# NUC505_v1 register map
File version: 1.0
Registers are 32-bit, read-write, reset 0x0 unless marked. A register's access mark holds for its fields unless they carry their own. Offsets are from the block's base; [hi:lo] are bit positions; {n}, {i} and the like mark numbered series.

## I2S — I2S Register Map
Base 0x400E8000
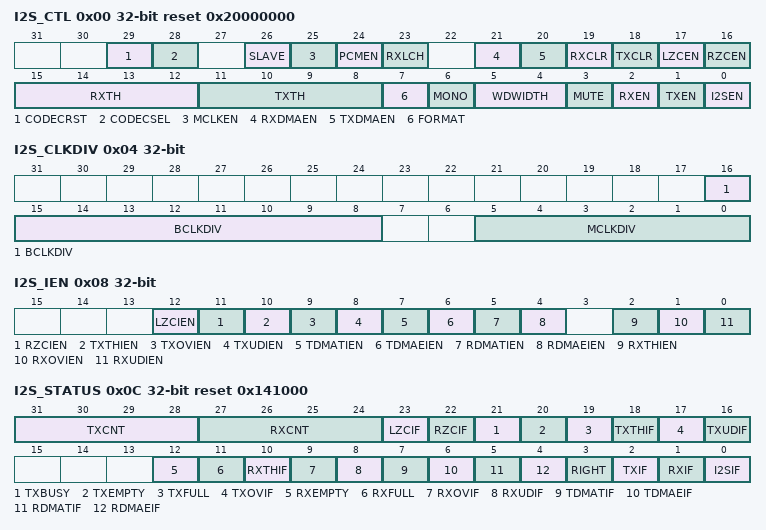
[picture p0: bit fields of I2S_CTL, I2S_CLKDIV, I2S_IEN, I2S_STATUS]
0x00 I2S_CTL reset 0x20000000 — I2S Control Register
  [29] CODECRST — Internal CODEC Hardware Reset Control
    0=Reset Operation; 1=Normal Operation
  [28] CODECSEL — Internal CODEC or External CODEC Selection
    0=I2S interface connected to internal CODEC; 1=I2S interface connected to external CODEC
  [26] SLAVE — Slave Mode. I2S can operate as master or slave. For Master mode, I2S_BCLK and I2S_LRCLK signals are output to CODEC. In Slave mode, I2S_BCLK and I2S_LRCLK pins are received from CODEC. Note: If using internal CODEC, the I2S must be master mode.
    0=Master mode; 1=Slave mode
  [25] MCLKEN — Master Clock Enable Control. Note1: I2S_MCLK is always output. Note2: I2S_MCLK frequency is controlled by MCLKDIV[5:0].
    0=I2S master clock output Disabled; 1=I2S master clock output Enabled
  [24] PCMEN — PCM Interface Enable Control
    0=I2S Interface; 1=PCM Interface
  [23] RXLCH — Receive Left Channel Enable Control
    0=Receives right channel data when monaural format is selected; 1=Receives left channel data when monaural format is selected
  [21] RXDMAEN — RX DMA Enable Control (Record Path). Note: The I2S_RXSTADDR will be updated to new setting only when RXDMAEN is from low to high. Therefore, if you want to change I2S_RXSTADDR, you should confirm RXDMAEN is disabled.
    0=RX DMA mode Disabled; 1=RX DMA mode Enabled
  [20] TXDMAEN — TX DMA Enable Control (Transmit Path). Note: The I2S_TXSTADDR will be updated to new setting only when TXDMAEN is from low to high. Therefore, if you want to change I2S_TXSTADDR, you should confirm TXDMAEN is disabled.
    0=TX DMA mode Disabled; 1=TX DMA mode Enabled
  [19] RXCLR — Clear Receive FIFO. Note: This bit will be cleared to 0 automatically. Note2: If clearing the receiver FIFO, RXCNT (I2S_STATUS[27:24]) returns to 0x0 and receiver FIFO becomes empty.
    0=No effect; 1=Receiver FIFO will be cleared
  [18] TXCLR — Clear Transmit FIFO. Note: This bit will be cleared to 0 automatically. Note2: If clearing the transmit FIFO, TXCNT (I2S_STATUS[31:28]) returns to 0x0 and transmit FIFO becomes empty.
    0=No effect; 1=Transmit FIFO will be cleared
  [17] LZCEN — Left Channel Zero-cross Detect Enable Control. If this bit is set to 1, when left channel data sign bit change or next shift data bits are all zero then LZCIF flag in I2S_STATUS register is set to 1.
    0=Left channel zero-cross detect Disabled; 1=Left channel zero-cross detect Enabled
  [16] RZCEN — Right Channel Zero-cross Detection Enable Control. If this bit is set to 1, when right channel data sign bit change or next shift data bits are all zero then RZCIF flag in I2S_STATUS register is set to 1.
    0=Right channel zero-cross detect Disabled; 1=Right channel zero-cross detect Enabled
  [15:12] RXTH — Receive FIFO Threshold Level. When received data word(s) in buffer is equal to or higher than threshold level then RXTHIF flag is set.
    {v}={v+1} word data in receive FIFO (v=0..15)
  [11:8] TXTH — Transmit FIFO Threshold Level. If remain data word (32 bits) in transmit FIFO is the same or less than threshold level then TXTHIF flag is set.
    0=0 word data in transmit FIFO; 1=1 word data in transmit FIFO; {v}={v} words data in transmit FIFO (v=2..7); 8=8 word data in transmit FIFO; 9=9 word data in transmit FIFO; {v}={v} words data in transmit FIFO (v=10..15)
  [7] FORMAT — Data Format Selection
    0=I2S data format. PCM mode A; 1=MSB justified data format. PCM mode B
  [6] MONO — Monaural Data
    0=Data is stereo format; 1=Data is monaural format
  [5:4] WDWIDTH — Word Width
    0=Data is 8-bit; 1=Data is 16-bit; 2=Data is 24-bit; 3=Data is 32-bit
  [3] MUTE — Transmit Mute Enable Control
    0=Transmit data is shifted from buffer; 1=Transmit data is fixed to zero
  [2] RXEN — Receive Enable Control
    0=Data receiving Disabled; 1=Data receiving Enabled
  [1] TXEN — Transmit Enable Control
    0=Data transmission Disabled; 1=Data transmission Enabled
  [0] I2SEN — I2S Controller Enable Control
    0=Disabled; 1=Enabled
0x04 I2S_CLKDIV — I2S Clock Divider Control Register
  [16:8] BCLKDIV — Bit Clock Divider. User can program these bits to generate the frequency of BCLK, when I2S operates in master mode. In Slave mode, the frequency of BCLK is controlled by master device.
  [5:0] MCLKDIV — Master Clock Divider. If F_I2SCLK is (2*MCLKDIV)*256*F_LRCLK then software can program these bits to generate 256*F_LRCLK clock frequency as master clock to audio CODEC. But if MCLKDIV is set to 0, MCLK is the same as I2SCLK input.
0x08 I2S_IEN — I2S Interrupt Enable Register
  [all] fields
    0=Interrupt Disabled; 1=Interrupt Enabled
  [12] LZCIEN — Left Channel Zero-cross Interrupt Enable Control. Interrupt occurs if this bit is set to 1 and left channel zero-cross is detected.
  [11] RZCIEN — Right Channel Zero-cross Interrupt Enable Control. Interrupt occurs if this bit is set to 1 and right channel zero-cross is detected.
  [10] TXTHIEN — Transmit FIFO Threshold Level Interrupt Enable Control. Interrupt occurs if this bit is set to 1 and data words in transmit FIFO is less than TXTH[3:0].
  [9] TXOVIEN — Transmit FIFO Overflow Interrupt Enable Control. Interrupt occurs if this bit is set to 1 and transmit FIFO overflow flag is set to 1.
  [8] TXUDIEN — Transmit FIFO Underflow Interrupt Enable Control. Interrupt occurs if this bit is set to 1 and transmit FIFO underflow flag is set to 1.
  [7] TDMATIEN — TX DMA Threshold Interrupt Enable Control. Interrupt occurs if this bit is set to 1 and DMA current address is equal to I2S_TXTHADDR register
  [6] TDMAEIEN — TX DMA End Interrupt Enable Control. Interrupt occurs if this bit is set to 1 and DMA current address is equal to I2S_TXEADDR register
  [5] RDMATIEN — RX DMA Threshold Interrupt Enable Control. Interrupt occurs if this bit is set to 1 and DMA current address is equal to I2S_RXTHADDR register
  [4] RDMAEIEN — RX DMA End Interrupt Enable Control. Interrupt occurs if this bit is set to 1 and DMA current address is equal to I2S_RXEADDR register
  [2] RXTHIEN — Receive FIFO Threshold Level Interrupt Enable Control. When data word in receive FIFO is equal to or higher then RXTH[3:0] and the RXTHIF bit is set to 1. If RXTHIEN bit is enabled, interrupt will occur.
  [1] RXOVIEN — Receive FIFO Overflow Interrupt Enable Control
  [0] RXUDIEN — Receive FIFO Underflow Interrupt Enable Control. If software reads receive FIFO when it is empty the RXUDIF flag in I2S_STATUS register is set to 1.
0x0C I2S_STATUS reset 0x141000
  [31:28] TXCNT — Transmit FIFO Level. These bits indicate word number in transmit FIFO
    0=No data or 16 words ( need to check the TX full flag); 1=1 word in transmit FIFO; 15=15 words in transmit FIFO
  [27:24] RXCNT — Receive FIFO Level. These bits indicate word number in receive FIFO
    0=No data or 16 words (need to check the RX full flag); 1=1 word in receive FIFO; 15=15 words in receive FIFO
  [23] LZCIF — Left Channel Zero-cross Flag. It indicates left channel next sample data sign bit is changed or all data bits are zero. Note: Write 1 to clear this bit to 0.
    0=No zero-cross; 1=Left channel zero-cross is detected
  [22] RZCIF — Right Channel Zero-cross Flag. It indicates right channel next sample data sign bit is changed or all data bits are zero. Note: Write 1 to clear this bit to 0.
    0=No zero-cross; 1=Right channel zero-cross is detected
  [21] TXBUSY — Transmit Busy. This bit is cleared to 0 when all data in transmit FIFO and shift buffer is shifted out. This bit is set to 1 when the first data is loaded to shift buffer. Note: This bit is read only.
    0=Transmit shift buffer is empty; 1=Transmit shift buffer is busy
  [20] TXEMPTY — Transmit FIFO Empty. This bit reflect data word number in transmit FIFO is zero. Note: This bit is read only.
    0=Not empty; 1=Empty
  [19] TXFULL — Transmit FIFO Full. This bit reflect data word number in transmit FIFO is 16. Note: This bit is read only.
    0=Not full; 1=Full
  [18] TXTHIF — Transmit FIFO Threshold Flag. When data word(s) in transmit FIFO is equal or lower than threshold value set in TXTH[3:0] the TXTHIF bit becomes to 1. It keeps at 1 till TXCNT[3:0] is higher than TXTH[3:0] after software write I2S_TX register. Note: This bit is read only.
    0=Data word(s) in FIFO is higher than threshold level; 1=Data word(s) in FIFO is equal or lower than threshold level
  [17] TXOVIF — Transmit FIFO Overflow Flag. Write data to transmit FIFO when it is full and this bit set to 1. Note: Write 1 to clear this bit to 0.
    0=No overflow; 1=Overflow
  [16] TXUDIF — Transmit FIFO Underflow Flag. When transmit FIFO is empty and shift logic hardware read data from data FIFO causes this set to 1. Note: Write 1 to clear this bit to 0.
    0=No underflow; 1=Underflow
  [12] RXEMPTY — Receive FIFO Empty. This bit reflects data words number in receive FIFO is zero. Note: This bit is read only.
    0=FIFO not empty; 1=FIFO empty
  [11] RXFULL — Receive FIFO Full. This bit reflect data words number in receive FIFO is 16. Note: This bit is read only.
    0=FIFO not full; 1=FIFO full
  [10] RXTHIF — Receive FIFO Threshold Flag. When data word(s) in receive FIFO is equal to or higher than the threshold value set in RXTH[3:0] the RXTHIF bit becomes to 1. It keeps at 1 till RXCNT[3:0] is less than RXTH[3:0] after software reads the I2S_RX register. Note: This bit is read only.
    0=Data word(s) in FIFO is lower than threshold level; 1=Data word(s) in FIFO is equal or higher than threshold level
  [9] RXOVIF — Receive FIFO Overflow Flag. When receive FIFO is full and receive hardware attempt write to data into receive FIFO this bit is set to 1, and data in 1st buffer is overwritten. Note: Write 1 to clear this bit to 0.
    0=No overflow occurred; 1=Overflow occurred
  [8] RXUDIF — Receive FIFO Underflow Flag. Read receive FIFO when it is empty. Setting this bit to 1 indicates underflow occurred. Note: Write 1 to clear this bit to zero
    0=No underflow occurred; 1=Underflow occurred
  [7] TDMATIF — TX DMA Equal Threshold Address Interrupt Flag. If TX DMA current address is equal to I2S_TXTHADDR register, this interrupt flag will be set. If the TDMATIEN is set, an interrupt to NVIC will occur. Note: Write 1 to clear this bit to zero
    0=No TX Threshold Interrupt; 1=TX Threshold Interrupt
  [6] TDMAEIF — TX DMA Equal End Address Interrupt Flag. If TX DMA current address is equal to I2S_TXEADDR register, this interrupt flag will be set. If the TDMAEIEN is set, an interrupt to NVIC will occur. Note: Write 1 to clear this bit to zero
    0=No TX End Interrupt; 1=TX End Interrupt
  [5] RDMATIF — RX DMA Equal Threshold Address Interrupt Flag. If RX DMA current address is equal to I2S_RXTHADDR register, this interrupt flag will be set. If the RDMATIEN is set, an interrupt to NVIC will occur. Note: Write 1 to clear this bit to zero
    0=No RX Threshold Interrupt; 1=RX Threshold Interrupt
  [4] RDMAEIF — RX DMA Equal End Address Interrupt Flag. If RX DMA current address is equal to I2S_RXEADDR register, this interrupt flag will be set. If the RDMAEIEN is set, an interrupt to NVIC will occur. Note: Write 1 to clear this bit to zero
    0=No RX End Interrupt; 1=RX End Interrupt
  [3] RIGHT — Right Channel. Indicates that the current transmit data belongs to right channel. Note: This bit is read only,
    0=Left channel; 1=Right channel
  [2] TXIF — I2S Transmit Interrupt. Note1: This flag is triggered if any of LZCIF, RZCIF, TXTHIF, TXOIF, TXUDIF, TDMATIF, and TDMAEIF occurs. Note2: This bit is read only.
    0=No transmit interrupt; 1=Transmit interrupt
  [1] RXIF — I2S Receive Interrupt. Note1: This flag is triggered if any of RXTHIF, RXOVIF, RXUDIF, RDMATIF, and RDMAEIF occurs. Note2: This bit is read only.
    0=No receive interrupt; 1=Receive interrupt
  [0] I2SIF — I2S Interrupt Flag. Note1: This flag is triggered if any of TXIF and RXIF bits are enabled. Note2: This bit is read only.
    0=No I2S interrupt; 1=I2S interrupt
0x10 I2S_TX wo — I2S Transmit FIFO Register
  [31:0] TX — Transmit FIFO Register. I2S contains 16 words (16x32 bit) data FIFO for data transmssion. Write data to this register to prepare data for transmission. The remaining word number is indicated by TXCNT[3:0] in I2S_STATUS.
0x14 I2S_RX ro — I2S Receive FIFO Register
  [31:0] RX — Receive FIFO Register. I2S contains 16 words (16x32 bit) data FIFO for data receiving. Read this register to get data in FIFO. The remaining data word number is indicated by RXCNT[3:0] in I2S_STATUS register.
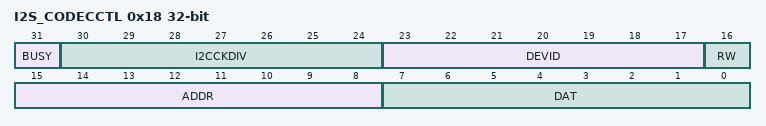
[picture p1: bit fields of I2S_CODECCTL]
0x18 I2S_CODECCTL — I2S Virtual I2C Control Register
  [31] BUSY — Busy Flag. If the register 'I2S_CODECCTL' has been written, the HW would change the command to the I2C format because the internal audio CODEC interface is I2C. However, the speed of the I2C is slow. Thus, this bit is used to indicate the end of the I2C command.
    0=I2C command is finished; 1=I2C command is not finished
  [30:24] I2CCKDIV — SCK Clock Divider. Control the SCK Timing Parameter. The SCK frequency is (F_I2SCLK / (I2CCKDIV * 16)). Note: Cannot be zero. Note2: F_SCK must be lower than or equal to F_MCLK / 16.
  [23:17] DEVID — Internal Audio CODEC Device ID. This parameter should be set to 40H.
  [16] RW — Read or Write Command. Control this command to read data from the internal audio CODEC or write data to.
    0=Read from the internal audio CODEC; 1=Write to the internal audio CODEC
  [15:8] ADDR — Address Information. This parameter is used to read from the internal audio CODEC or write to the internal audio CODEC.
  [7:0] DAT — Data Information. This parameter is used to read from the internal audio CODEC or write to the internal audio CODEC.
0x20 I2S_TXSTADDR reset 0x20010000 — I2S TX DMA Start Address Register
  [31:0] ADDR — TX DMA Start Address Register. Note1: The address is word boundary. Note2: The address can't be set smaller than 0x2000_0000.
0x24 I2S_TXTHADDR reset 0x2001FFF0 — I2S TX DMA Threshold Address Register
  [31:0] ADDR — TX DMA Threshold Address Register. Note1: The address is word boundary. Note2: The address can't be set smaller than 0x2000_0000.
0x28 I2S_TXEADDR reset 0x2001FFF0 — I2S TX DMA End Address Register
  [31:0] ADDR — TX DMA End Address Register. Note1: The address is word boundary. Note2: If WDWIDTH[1:0] is equal to 0x2 or 0x3, user must set the correct end address to avoid the swap between right channel and left channel in stereo mode. Note2: The address can't be set smaller than 0x2000_0000.
0x2C I2S_TXCADDR ro — I2S TX DMA Current Address Register
  [31:0] ADDR — TX DMA Current Address Register
0x30 I2S_RXSTADDR reset 0x20010000 — I2S RX DMA Start Address Register
  [31:0] ADDR — RX DMA Start Address Register. Note1: The address is word boundary. Note2: The address can't be set smaller than 0x2000_0000.
0x34 I2S_RXTHADDR reset 0x2001FFF0 — I2S RX DMA Threshold Address Register
  [31:0] ADDR — RX DMA Threshold Address Register. Note1: The address is word boundary. Note2: The address can't be set smaller than 0x2000_0000.
0x38 I2S_RXEADDR reset 0x2001FFF0 — I2S RX DMA End Address Register
  [31:0] ADDR — RX DMA End Address Register. Note1: The address is word boundary. Note2: If WDWIDTH[1:0] is equal to 0x2 or 0x3, user must set the correct end address to avoid the swap between right channel and left channel in stereo mode. Note3: The address can't be set smaller than 0x2000_0000.
0x3C I2S_RXCADDR ro — I2S RX DMA Current Address Register
  [31:0] ADDR — RX DMA Current Address Register
0x40 I2S_RXAVGCTL reset 0xA — I2S RX Data Average Control Register
  [3:0] WINSEL — RX Data Average Window Select. Note: Every window size samples will generate one average result.
    0=Average window is 1 (2^0) sample; 1=Average window is 2 (2^1) samples; 2=Average window is 4 (2^2) samples; 14=Average window is 16384 (2^14) samples; 15=Average window is 32768 (2^15) samples
0x44 I2S_RXLCHAVG ro — I2S RX Left Channel Data Average
  [31:0] RESULT — RX Left Channel Data Average Result. The average result of left channel received data.
0x48 I2S_RXRCHAVG ro — I2S RX Right Channel Data Average
  [31:0] RESULT — RX Right Channel Data Average Result. The average result of left channel received data. Note: If MONO (I2S_CTL[6]), this register will be useless.
